AUTOSAR XML (schema 4-0-3)
package /APTIV_MODEL_APP/ComponentType
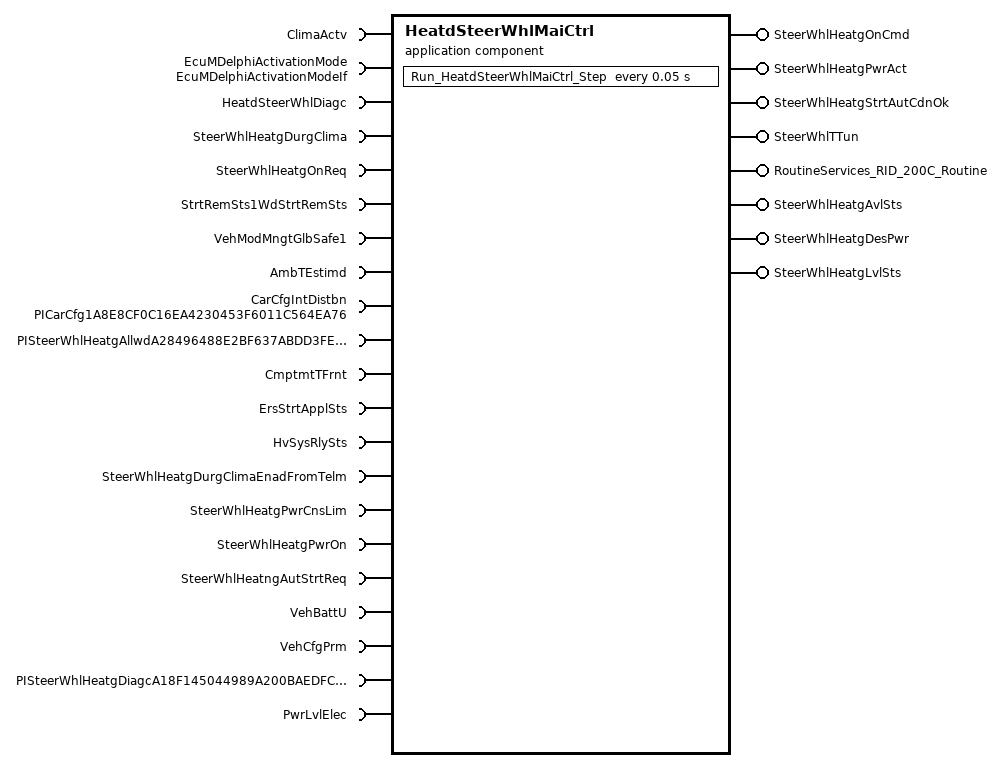
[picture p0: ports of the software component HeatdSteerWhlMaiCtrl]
  application sw component type HeatdSteerWhlMaiCtrl
    7 x require port:
      ClimaActv: nonqueued-receiver-com-spec{data-element=ClimaActv, init-value=constant-reference=ClimaActv}, required-interface=ClimaActv
      EcuMDelphiActivationMode: mode-switch-receiver-com-spec=supports-asynchronous-mode-switch=false, required-interface=EcuMDelphiActivationModeIf
      HeatdSteerWhlDiagc: nonqueued-receiver-com-spec{data-element=HeatdSteerWhlDiagc, init-value=constant-reference=HeatdSteerWhlDiagc}, required-interface=HeatdSteerWhlDiagc
      SteerWhlHeatgDurgClima: nonqueued-receiver-com-spec{data-element=SteerWhlHeatgDurgClima, init-value=constant-reference=SteerWhlHeatgDurgClima}, required-interface=SteerWhlHeatgDurgClima
      SteerWhlHeatgOnReq: nonqueued-receiver-com-spec{data-element=SteerWhlHeatgOnReq, init-value=constant-reference=SteerWhlHeatgOnReq}, required-interface=SteerWhlHeatgOnReq
      StrtRemSts1WdStrtRemSts: nonqueued-receiver-com-spec{data-element=StrtRemSts1WdStrtRemSts, init-value=constant-reference=StrtRemSts1WdStrtRemSts}, required-interface=StrtRemSts1WdStrtRemSts
      VehModMngtGlbSafe1: nonqueued-receiver-com-spec{data-element=VehModMngtGlbSafe1, init-value=constant-reference=VehModMngtGlbSafe1}, required-interface=VehModMngtGlbSafe1
    4 x provide port:
      SteerWhlHeatgOnCmd: nonqueued-sender-com-spec{data-element=SteerWhlHeatgOnCmd, init-value=constant-reference=SteerWhlHeatgOnCmd}, provided-interface=SteerWhlHeatgOnCmd
      SteerWhlHeatgPwrAct: nonqueued-sender-com-spec{data-element=SteerWhlHeatgPwrAct, init-value=constant-reference=SteerWhlHeatgPwrAct}, provided-interface=SteerWhlHeatgPwrAct
      SteerWhlHeatgStrtAutCdnOk: nonqueued-sender-com-spec{data-element=SteerWhlHeatgStrtAutCdnOk, init-value=constant-reference=SteerWhlHeatgStrtAutCdnOk}, provided-interface=SteerWhlHeatgStrtAutCdnOk
      SteerWhlTTun: nonqueued-sender-com-spec{data-element=SteerWhlTTun, init-value=constant-reference=SteerWhlTTun}, provided-interface=SteerWhlTTun
    require port AmbTEstimd: nonqueued-receiver-com-spec{data-element=AmbTEstimd, init-value=constant-reference=AmbTEstimd}, required-interface=AmbTEstimd
    require port CarCfgIntDistbn: required-interface=PICarCfg1A8E8CF0C16EA4230453F6011C564EA76
      required-com-specs:
        data-element=CarCfg13, init-value=constant-reference=CarCfgIntDistbn_CarCfg13_InitValue
        data-element=CarCfg186, init-value=constant-reference=CarCfgIntDistbn_CarCfg186_InitValue
    provide port RoutineServices_RID_200C_Routine: provided-interface=RoutineServices_RID_200C_Routine
    require port PISteerWhlHeatgAllwdA28496488E2BF637ABDD3FED0272E814: nonqueued-receiver-com-spec=data-element=SteerWhlHeatgAllwd, required-interface=PISteerWhlHeatgAllwdA28496488E2BF637ABDD3FED0272E814
    provide port SteerWhlHeatgAvlSts: nonqueued-sender-com-spec{data-element=SteerWhlHeatgAvlSts, init-value=constant-reference=SteerWhlHeatgAvlSts}, provided-interface=SteerWhlHeatgAvlSts
    provide port SteerWhlHeatgDesPwr: nonqueued-sender-com-spec{data-element=SteerWhlHeatgDesPwr, init-value=constant-reference=SteerWhlHeatgDesPwr}, provided-interface=SteerWhlHeatgDesPwr
    provide port SteerWhlHeatgLvlSts: nonqueued-sender-com-spec{data-element=SteerWhlHeatgLvlSts, init-value=constant-reference=SteerWhlHeatgLvlSts}, provided-interface=SteerWhlHeatgLvlSts
    11 x require port:
      CmptmtTFrnt: nonqueued-receiver-com-spec{data-element=CmptmtTFrnt, init-value=constant-reference=CmptmtTFrnt}, required-interface=CmptmtTFrnt
      ErsStrtApplSts: nonqueued-receiver-com-spec{data-element=ErsStrtApplSts, init-value=constant-reference=ErsStrtApplSts}, required-interface=ErsStrtApplSts
      HvSysRlySts: nonqueued-receiver-com-spec{data-element=HvSysRlySts, init-value=constant-reference=HvSysRlySts}, required-interface=HvSysRlySts
      SteerWhlHeatgDurgClimaEnadFromTelm: nonqueued-receiver-com-spec{data-element=SteerWhlHeatgDurgClimaEnadFromTelm, init-value=constant-reference=SteerWhlHeatgDurgClimaEnadFromTelm}, required-interface=SteerWhlHeatgDurgClimaEnadFromTelm
      SteerWhlHeatgPwrCnsLim: nonqueued-receiver-com-spec{data-element=SteerWhlHeatgPwrCnsLim, init-value=constant-reference=SteerWhlHeatgPwrCnsLim}, required-interface=SteerWhlHeatgPwrCnsLim
      SteerWhlHeatgPwrOn: nonqueued-receiver-com-spec{data-element=SteerWhlHeatgPwrOn, init-value=constant-reference=SteerWhlHeatgPwrOn}, required-interface=SteerWhlHeatgPwrOn
      SteerWhlHeatngAutStrtReq: nonqueued-receiver-com-spec{data-element=SteerWhlHeatngAutStrtReq, init-value=constant-reference=SteerWhlHeatngAutStrtReq}, required-interface=SteerWhlHeatngAutStrtReq
      VehBattU: nonqueued-receiver-com-spec{data-element=VehBattU, init-value=constant-reference=VehBattU}, required-interface=VehBattU
      VehCfgPrm: nonqueued-receiver-com-spec{data-element=VehCfgPrm, init-value=constant-reference=VehCfgPrm}, required-interface=VehCfgPrm
      PISteerWhlHeatgDiagcA18F145044989A200BAEDFC0428E4484: nonqueued-receiver-com-spec=data-element=SteerWhlHeatgDiagc, required-interface=PISteerWhlHeatgDiagcA18F145044989A200BAEDFC0428E4484
      PwrLvlElec: nonqueued-receiver-com-spec{data-element=PwrLvlElec, init-value=constant-reference=PwrLvlElec}, required-interface=PwrLvlElec
    behavior IBHeatdSteerWhlMaiCtrl: data-type-mapping=[DataTypeMappingSet, DataTypeMappingSetIntMod], handle-termination-and-restart=NO-SUPPORT
      swc mode switch event HeatdSteerWhlMaiCtrlInit: start-on-event=Run_HeatdSteerWhlMaiCtrl_Init, activation=ON-ENTRY, mode=EcuMDelphiActivationMode.EcuMDelphiActivationMode.DELPHI_ACTIVE
      timing event HeatdSteerWhlMaiCtrlStep: disabled-mode=EcuMDelphiActivationMode.EcuMDelphiActivationMode.DELPHI_NOT_ACTIVE, start-on-event=Run_HeatdSteerWhlMaiCtrl_Step, period=0.05
      operation invoked event OpInvokedEv_RoutineServices_RID_200C_Routine_RequestResults: start-on-event=HeatdSteerWhlMaiCtrl_RoutineServices_RID_200C_Routine_RequestResults, operation=RoutineServices_RID_200C_Routine.RequestResults
      operation invoked event OpInvokedEv_RoutineServices_RID_200C_Routine_Start: start-on-event=HeatdSteerWhlMaiCtrl_RoutineServices_RID_200C_Routine_Start, operation=RoutineServices_RID_200C_Routine.Start
      operation invoked event OpInvokedEv_RoutineServices_RID_200C_Routine_Stop: start-on-event=HeatdSteerWhlMaiCtrl_RoutineServices_RID_200C_Routine_Stop, operation=RoutineServices_RID_200C_Routine.Stop
      data send completed event DataSendCompletedEv1: start-on-event=Run_HeatdSteerWhlMaiCtrl_Step, event-source=SendPoint_SteerWhlHeatgDesPwr_SteerWhlHeatgDesPwr
      data send completed event DataSendCompletedEv2: start-on-event=Run_HeatdSteerWhlMaiCtrl_Step, event-source=SendPoint_SteerWhlHeatgLvlSts_SteerWhlHeatgLvlSts
      5 x runnable:
        Run_HeatdSteerWhlMaiCtrl_Init: sw-addr-method=APTIV_RUN
        Run_HeatdSteerWhlMaiCtrl_Step: sw-addr-method=APTIV_RUN, mode-access-point=EcuMDelphiActivationMode.EcuMDelphiActivationMode
          data-receive-point-by-arguments:
            29 x access:
              IN_ClimaActv_ClimaActv: accessed-variable=ClimaActv.ClimaActv
              IN_SeatHeatgAutCdn_SeatHeatgAutCdn: accessed-variable=SeatHeatgAutCdn
              IN_SteerWhlHeatgAllwd_SteerWhlHeatgAllwd: accessed-variable=SteerWhlHeatgAllwd
              IN_SteerWhlHeatgDurgClima_SteerWhlHeatgDurgClima: accessed-variable=SteerWhlHeatgDurgClima.SteerWhlHeatgDurgClima
              IN_SteerWhlHeatgOnReq_SteerWhlHeatgOnReq: accessed-variable=SteerWhlHeatgOnReq.SteerWhlHeatgOnReq
              IN_SteerWhlHeatngAutStrtSelected_SteerWhlHeatgOnCmdTyp: accessed-variable=SteerWhlHeatgOnCmdTyp
              IN_StrtRemSts_StrtRemSts: accessed-variable=StrtRemSts1WdStrtRemSts.StrtRemSts1WdStrtRemSts
              IN_VehModMngtGlbSafe1_VehModMngtGlbSafe1: accessed-variable=VehModMngtGlbSafe1.VehModMngtGlbSafe1
              IN_AmbTEstimd_AmbTEstimd: accessed-variable=AmbTEstimd.AmbTEstimd
              IN_CarCfgIntDistbn_CarCfg13: accessed-variable=CarCfgIntDistbn.CarCfg13
              IN_CarCfgIntDistbn_CarCfg186: accessed-variable=CarCfgIntDistbn.CarCfg186
              IN_HeatdSteerWhlDiagc_HeatdSteerWhlDiagc: accessed-variable=HeatdSteerWhlDiagc.HeatdSteerWhlDiagc
              ArgRecPoint_CarCfgIntDistbn_CarCfg169: accessed-variable=CarCfgIntDistbn.CarCfg169
              ArgRecPoint_CarCfgIntDistbn_CarCfg182: accessed-variable=CarCfgIntDistbn.CarCfg182
              ArgRecPoint_CarCfgIntDistbn_CarCfg13: accessed-variable=CarCfgIntDistbn.CarCfg13
              ArgRecPoint_CarCfgIntDistbn_CarCfg186: accessed-variable=CarCfgIntDistbn.CarCfg186
              ArgRecPoint_PISteerWhlHeatgAllwdA28496488E2BF637ABDD3FED0272E814_SteerWhlHeatgAllwd: accessed-variable=PISteerWhlHeatgAllwdA28496488E2BF637ABDD3FED0272E814.SteerWhlHeatgAllwd
              ArgRecPoint_CmptmtTFrnt_CmptmtTFrnt: accessed-variable=CmptmtTFrnt.CmptmtTFrnt
              ArgRecPoint_ErsStrtApplSts_ErsStrtApplSts: accessed-variable=ErsStrtApplSts.ErsStrtApplSts
              ArgRecPoint_HvSysRlySts_HvSysRlySts: accessed-variable=HvSysRlySts.HvSysRlySts
              ArgRecPoint_SteerWhlHeatgDurgClimaEnadFromTelm_SteerWhlHeatgDurgClimaEnadFromTelm: accessed-variable=SteerWhlHeatgDurgClimaEnadFromTelm.SteerWhlHeatgDurgClimaEnadFromTelm
              ArgRecPoint_SteerWhlHeatngAutStrtReq_SteerWhlHeatngAutStrtReq: accessed-variable=SteerWhlHeatngAutStrtReq.SteerWhlHeatngAutStrtReq
              ArgRecPoint_VehBattU_VehBattU: accessed-variable=VehBattU.VehBattU
              ArgRecPoint_VehCfgPrm_VehCfgPrm: accessed-variable=VehCfgPrm.VehCfgPrm
              ArgRecPoint_PISteerWhlHeatgDiagcA18F145044989A200BAEDFC0428E4484_SteerWhlHeatgDiagc: accessed-variable=PISteerWhlHeatgDiagcA18F145044989A200BAEDFC0428E4484.SteerWhlHeatgDiagc
              ArgRecPoint_PwrLvlElec_PwrLvlElec: accessed-variable=PwrLvlElec.PwrLvlElec
              ArgRecPoint_SteerWhlHeatgPwrCnsLim_SteerWhlHeatgPwrCnsLim: accessed-variable=SteerWhlHeatgPwrCnsLim.SteerWhlHeatgPwrCnsLim
              ArgRecPoint_SteerWhlHeatgPwrOn_SteerWhlHeatgPwrOn: accessed-variable=SteerWhlHeatgPwrOn.SteerWhlHeatgPwrOn
              ArgRecPoint_VehModMngtGlbSafe1_VehModMngtGlbSafe1: accessed-variable=VehModMngtGlbSafe1.VehModMngtGlbSafe1
          data-send-points:
            7 x access:
              OUT_SteerWhlHeatgOnCmd_SteerWhlHeatgOnCmd: accessed-variable=SteerWhlHeatgOnCmd.SteerWhlHeatgOnCmd
              OUT_SteerWhlHeatgPwrAct_SteerWhlHeatgPwrAct: accessed-variable=SteerWhlHeatgPwrAct.SteerWhlHeatgPwrAct
              OUT_SteerWhlHeatgStrtAutCdnOk_SteerWhlHeatgStrtAutCdnOk: accessed-variable=SteerWhlHeatgStrtAutCdnOk.SteerWhlHeatgStrtAutCdnOk
              OUT_SteerWhlTTun_SteerWhlTTun: accessed-variable=SteerWhlTTun.SteerWhlTTun
              SendPoint_SteerWhlHeatgAvlSts_SteerWhlHeatgAvlSts: accessed-variable=SteerWhlHeatgAvlSts.SteerWhlHeatgAvlSts
              SendPoint_SteerWhlHeatgDesPwr_SteerWhlHeatgDesPwr: accessed-variable=SteerWhlHeatgDesPwr.SteerWhlHeatgDesPwr
              SendPoint_SteerWhlHeatgLvlSts_SteerWhlHeatgLvlSts: accessed-variable=SteerWhlHeatgLvlSts.SteerWhlHeatgLvlSts
          parameter access SCALPRM_SteerWhlTTunOffset: accessed-parameter=SteerWhlTTunOffset
        HeatdSteerWhlMaiCtrl_RoutineServices_RID_200C_Routine_RequestResults: symbol=sym_HeatdSteerWhlMaiCtrl_RoutineServices_RID_200C_RequestResults
        HeatdSteerWhlMaiCtrl_RoutineServices_RID_200C_Routine_Start: symbol=sym_HeatdSteerWhlMaiCtrl_RoutineServices_RID_200C_Start
        HeatdSteerWhlMaiCtrl_RoutineServices_RID_200C_Routine_Stop: symbol=sym_HeatdSteerWhlMaiCtrl_RoutineServices_RID_200C_Stop
      shared-parameters:
        parameter data prototype SteerWhlTTunOffset: sw-addr-method=APTIV_CAL, sw-calibration-access=READ-WRITE, sw-impl-policy=CONST, type=SInt8, init-value=constant-reference=SteerWhlTTunOffset
  swc implementation ImplHeatdSteerWhlMaiCtrl: programming-language=C, sw-version=4.0.2, used-code-generator=hand coded, vendor-id=41, behavior=IBHeatdSteerWhlMaiCtrl
    code-descriptors:
      code Code: artifact-descriptors=autosar-engineering-object={short-label=dummy_c, category=dummy}
    resource consumption ResConsumption1
package /APTIV_MODEL_APP/Calibration/HeatdSteerWhlMaiCtrl
  constant specification SteerWhlTTunOffset: value-spec=0
  constant specification SteerWhlTTunOffset_InitValue
